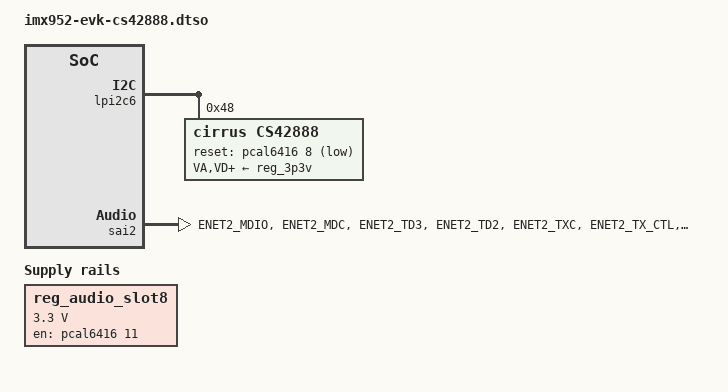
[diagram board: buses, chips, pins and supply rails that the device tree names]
// SPDX-License-Identifier: (GPL-2.0+ OR MIT)
/*
 * Copyright 2026 NXP
 */

/dts-v1/;
/plugin/;

#include <dt-bindings/gpio/gpio.h>
#include "imx952-clock.h"
#include "imx952-pinfunc.h"

&{/} {
	reg_audio_slot8: regulator-audio-slot8 {
		compatible = "regulator-fixed";
		regulator-name = "audio-slot8-switch";
		regulator-min-microvolt = <3300000>;
		regulator-max-microvolt = <3300000>;
		gpio = <&pcal6416 11 GPIO_ACTIVE_HIGH>;
		enable-active-high;
		regulator-always-on;
		regulator-boot-on;
	};

	sound-cs42888 {
		compatible = "fsl,imx-audio-card";
		model = "imx-cs42888";
		pri-dai-link {
			link-name = "cs42888";
			format = "i2s";
			fsl,mclk-equal-bclk;
			cpu {
				sound-dai = <&sai2>;
			};
			codec {
				sound-dai = <&cs42888>;
			};
		};
	};
};

&lpi2c6 {
	#address-cells = <1>;
	#size-cells = <0>;

	cs42888: codec@48 {
		compatible = "cirrus,cs42888";
		#sound-dai-cells = <0>;
		reg = <0x48>;
		clocks = <&scmi_clk IMX952_CLK_SAI2>;
		clock-names = "mclk";
		VA-supply = <&reg_3p3v>;
		VD-supply = <&reg_3p3v>;
		VLS-supply = <&reg_3p3v>;
		VLC-supply = <&reg_3p3v>;
		reset-gpios = <&pcal6416 8 GPIO_ACTIVE_LOW>;
	};
};

&sai2 {
	pinctrl-names = "default";
	pinctrl-0 = <&pinctrl_sai2>;
	clocks = <&scmi_clk IMX952_CLK_BUSNETCMIX>, <&clk_dummy>,
		 <&scmi_clk IMX952_CLK_SAI2>, <&clk_dummy>,
		 <&clk_dummy>, <&scmi_clk IMX952_CLK_AUDIOPLL1>,
		 <&scmi_clk IMX952_CLK_AUDIOPLL2>;
	clock-names = "bus", "mclk0", "mclk1", "mclk2", "mclk3", "pll8k", "pll11k";
	assigned-clocks = <&scmi_clk IMX952_CLK_AUDIOPLL1_VCO>,
			  <&scmi_clk IMX952_CLK_AUDIOPLL2_VCO>,
			  <&scmi_clk IMX952_CLK_AUDIOPLL1>,
			  <&scmi_clk IMX952_CLK_AUDIOPLL2>,
			  <&scmi_clk IMX952_CLK_SAI2>;
	assigned-clock-parents = <0>, <0>, <0>, <0>,
				 <&scmi_clk IMX952_CLK_AUDIOPLL1>;
	assigned-clock-rates = <3932160000>, <3612672000>,
			       <393216000>, <361267200>, <12288000>;
	fsl,sai-mclk-direction-output;
	fsl,sai-asynchronous;
	status = "okay";
};

&scmi_iomuxc {
	pinctrl_sai2: sai2grp {
		fsl,pins = <
			IMX952_PAD_ENET2_MDIO__NETCMIX_TOP_SAI2_RX_BCLK		0x31e
			IMX952_PAD_ENET2_MDC__NETCMIX_TOP_SAI2_RX_SYNC		0x31e
			IMX952_PAD_ENET2_TD3__NETCMIX_TOP_SAI2_RX_DATA_0	0x31e
			IMX952_PAD_ENET2_TD2__NETCMIX_TOP_SAI2_RX_DATA_1	0x31e
			IMX952_PAD_ENET2_TXC__NETCMIX_TOP_SAI2_TX_BCLK		0x31e
			IMX952_PAD_ENET2_TX_CTL__NETCMIX_TOP_SAI2_TX_SYNC	0x31e
			IMX952_PAD_ENET2_RX_CTL__NETCMIX_TOP_SAI2_TX_DATA_0	0x31e
			IMX952_PAD_ENET2_RXC__NETCMIX_TOP_SAI2_TX_DATA_1	0x31e
			IMX952_PAD_ENET2_RD0__NETCMIX_TOP_SAI2_TX_DATA_2	0x31e
			IMX952_PAD_ENET2_RD1__NETCMIX_TOP_SAI2_TX_DATA_3	0x31e
			IMX952_PAD_ENET2_RD2__NETCMIX_TOP_SAI2_MCLK		0x31e
		>;
	};
};
